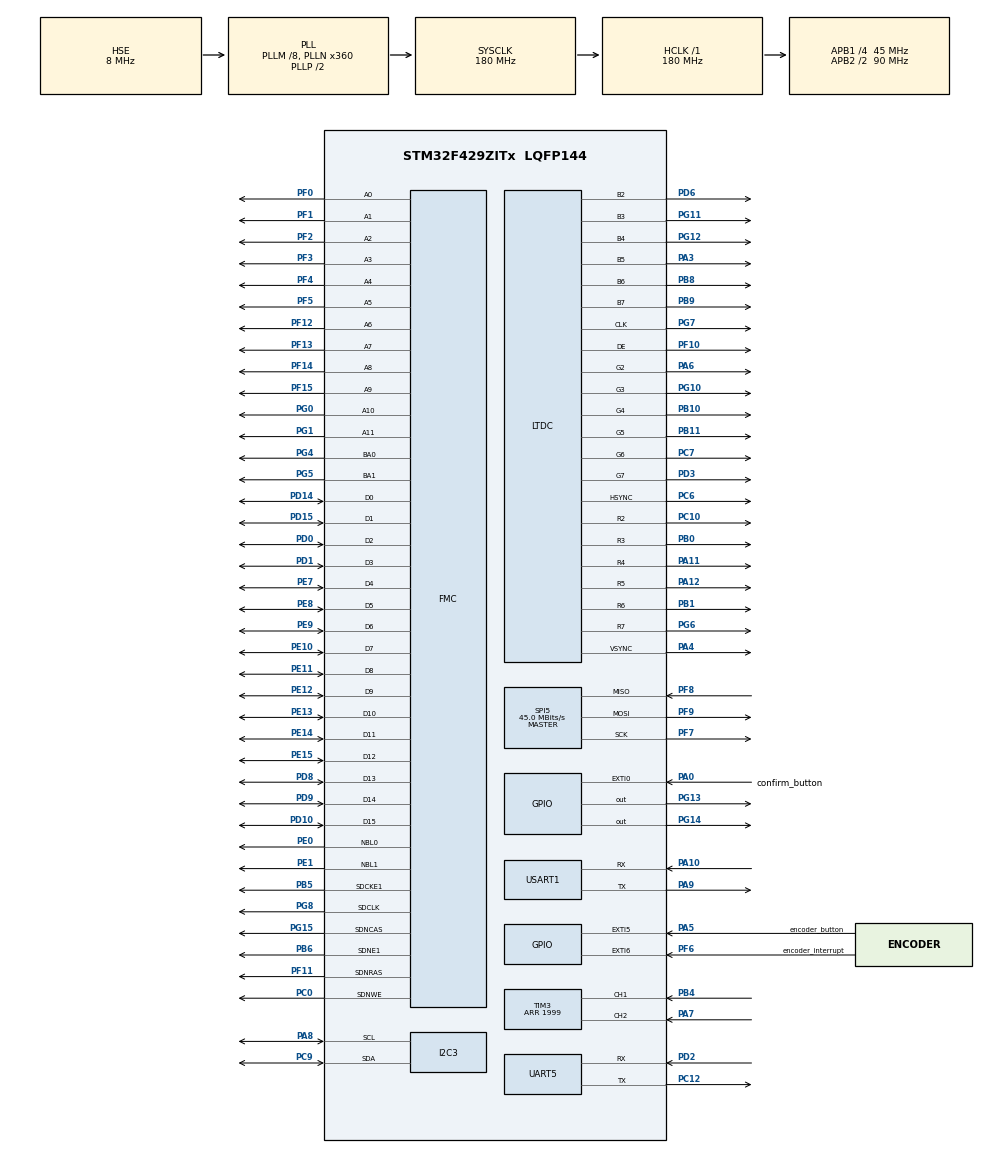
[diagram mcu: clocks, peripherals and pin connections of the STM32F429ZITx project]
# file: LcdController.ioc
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DMA2D.ColorMode=DMA2D_OUTPUT_RGB565
LTDC.ActiveH=320
LTDC.ActiveW=240
Mcu.Family=STM32F4
Mcu.Name=STM32F429ZITx
Mcu.Package=LQFP144
NVIC.EXTI0_IRQn=true\:1\:0\:true\:false\:true\:true\:true\:true
NVIC.EXTI9_5_IRQn=true\:2\:0\:true\:false\:true\:true\:true\:true
NVIC.PriorityGroup=NVIC_PRIORITYGROUP_4
NVIC.UART5_IRQn=true\:0\:0\:true\:false\:true\:true\:true\:true
PA0/WKUP.GPIO_Label=confirm_button
PA0/WKUP.GPIO_ModeDefaultEXTI=GPIO_MODE_IT_RISING
PA0/WKUP.GPIO_PuPd=GPIO_PULLDOWN
PA0/WKUP.Signal=GPXTI0
PA10.Mode=Asynchronous
PA10.Signal=USART1_RX
PA11.Mode=RGB666
PA11.Signal=LTDC_R4
PA12.Mode=RGB666
PA12.Signal=LTDC_R5
PA3.Mode=RGB666
PA3.Signal=LTDC_B5
PA4.Mode=RGB666
PA4.Signal=LTDC_VSYNC
PA5.GPIO_Label=encoder_button
PA5.GPIO_ModeDefaultEXTI=GPIO_MODE_IT_FALLING
PA5.GPIO_PuPd=GPIO_NOPULL
PA5.Signal=GPXTI5
PA6.Mode=RGB666
PA6.Signal=LTDC_G2
PA7.Signal=S_TIM3_CH2
PA8.Mode=I2C
PA8.Signal=I2C3_SCL
PA9.Mode=Asynchronous
PA9.Signal=USART1_TX
PB0.Mode=RGB666
PB0.Signal=LTDC_R3
PB1.Mode=RGB666
PB1.Signal=LTDC_R6
PB10.Mode=RGB666
PB10.Signal=LTDC_G4
PB11.Mode=RGB666
PB11.Signal=LTDC_G5
PB4.Signal=S_TIM3_CH1
PB5.Mode=SdramChipSelect2_1
PB5.Signal=FMC_SDCKE1
PB6.Mode=SdramChipSelect2_1
PB6.Signal=FMC_SDNE1
PB8.Mode=RGB666
PB8.Signal=LTDC_B6
PB9.Mode=RGB666
PB9.Signal=LTDC_B7
PC0.Signal=FMC_SDNWE
PC10.Mode=RGB666
PC10.Signal=LTDC_R2
PC12.Mode=Asynchronous
PC12.Signal=UART5_TX
PC6.Mode=RGB666
PC6.Signal=LTDC_HSYNC
PC7.Mode=RGB666
PC7.Signal=LTDC_G6
PC9.Mode=I2C
PC9.Signal=I2C3_SDA
PD0.Signal=FMC_D2_DA2
PD1.Signal=FMC_D3_DA3
PD10.Signal=FMC_D15_DA15
PD14.Signal=FMC_D0_DA0
PD15.Signal=FMC_D1_DA1
PD2.Mode=Asynchronous
PD2.Signal=UART5_RX
PD3.Mode=RGB666
PD3.Signal=LTDC_G7
PD6.Mode=RGB666
PD6.Signal=LTDC_B2
PD8.Signal=FMC_D13_DA13
PD9.Signal=FMC_D14_DA14
PE0.Signal=FMC_NBL0
PE1.Signal=FMC_NBL1
PE10.Signal=FMC_D7_DA7
PE11.Signal=FMC_D8_DA8
PE12.Signal=FMC_D9_DA9
PE13.Signal=FMC_D10_DA10
PE14.Signal=FMC_D11_DA11
PE15.Signal=FMC_D12_DA12
PE7.Signal=FMC_D4_DA4
PE8.Signal=FMC_D5_DA5
PE9.Signal=FMC_D6_DA6
PF0.Signal=FMC_A0
PF1.Signal=FMC_A1
PF10.Mode=RGB666
PF10.Signal=LTDC_DE
PF11.Signal=FMC_SDNRAS
PF12.Signal=FMC_A6
PF13.Signal=FMC_A7
PF14.Signal=FMC_A8
PF15.Signal=FMC_A9
PF2.Signal=FMC_A2
PF3.Signal=FMC_A3
PF4.Signal=FMC_A4
PF5.Signal=FMC_A5
PF6.GPIO_Label=encoder_interrupt
PF6.GPIO_ModeDefaultEXTI=GPIO_MODE_IT_FALLING
PF6.Signal=GPXTI6
PF7.Mode=Full_Duplex_Master
PF7.Signal=SPI5_SCK
PF8.Mode=Full_Duplex_Master
PF8.Signal=SPI5_MISO
PF9.Mode=Full_Duplex_Master
PF9.Signal=SPI5_MOSI
PG0.Signal=FMC_A10
PG1.Signal=FMC_A11
PG10.Mode=RGB666
PG10.Signal=LTDC_G3
PG11.Mode=RGB666
PG11.Signal=LTDC_B3
PG12.Mode=RGB666
PG12.Signal=LTDC_B4
PG13.Signal=GPIO_Output
PG14.Signal=GPIO_Output
PG15.Signal=FMC_SDNCAS
PG4.Signal=FMC_A14_BA0
PG5.Signal=FMC_A15_BA1
PG6.Mode=RGB666
PG6.Signal=LTDC_R7
PG7.Mode=RGB666
PG7.Signal=LTDC_CLK
PG8.Signal=FMC_SDCLK
PH0/OSC_IN.Mode=HSE-External-Oscillator
PH0/OSC_IN.Signal=RCC_OSC_IN
PH1/OSC_OUT.Mode=HSE-External-Oscillator
PH1/OSC_OUT.Signal=RCC_OSC_OUT
ProjectManager.HeapSize=0x200
ProjectManager.StackSize=0x400
ProjectManager.TargetToolchain=EWARM V8.50
RCC.48MHZClocksFreq_Value=90000000
RCC.AHBFreq_Value=180000000
RCC.APB1CLKDivider=RCC_HCLK_DIV4
RCC.APB1Freq_Value=45000000
RCC.APB1TimFreq_Value=90000000
RCC.APB2CLKDivider=RCC_HCLK_DIV2
RCC.APB2Freq_Value=90000000
RCC.APB2TimFreq_Value=180000000
RCC.CortexFreq_Value=180000000
RCC.HCLKFreq_Value=180000000
RCC.HSE_VALUE=8000000
RCC.HSI_VALUE=16000000
RCC.LSE_VALUE=32768
RCC.PLLM=8
RCC.PLLN=360
RCC.PLLSAIDivR=RCC_PLLSAIDIVR_16
RCC.PLLSAIN=192
RCC.PLLSourceVirtual=RCC_PLLSOURCE_HSE
RCC.SYSCLKFreq_VALUE=180000000
RCC.SYSCLKSource=RCC_SYSCLKSOURCE_PLLCLK
RCC.VCOOutputFreq_Value=360000000
SH.FMC_A0.0=FMC_A0,12b-sda1
SH.FMC_A1.0=FMC_A1,12b-sda1
SH.FMC_A10.0=FMC_A10,12b-sda1
SH.FMC_A11.0=FMC_A11,12b-sda1
SH.FMC_A14_BA0.0=FMC_BA0,FourSdramBanks1
SH.FMC_A15_BA1.0=FMC_BA1,FourSdramBanks1
SH.FMC_A2.0=FMC_A2,12b-sda1
SH.FMC_A3.0=FMC_A3,12b-sda1
SH.FMC_A4.0=FMC_A4,12b-sda1
SH.FMC_A5.0=FMC_A5,12b-sda1
SH.FMC_A6.0=FMC_A6,12b-sda1
SH.FMC_A7.0=FMC_A7,12b-sda1
SH.FMC_A8.0=FMC_A8,12b-sda1
SH.FMC_A9.0=FMC_A9,12b-sda1
SH.FMC_D0_DA0.0=FMC_D0,sd-16b-d1
SH.FMC_D10_DA10.0=FMC_D10,sd-16b-d1
SH.FMC_D11_DA11.0=FMC_D11,sd-16b-d1
SH.FMC_D12_DA12.0=FMC_D12,sd-16b-d1
SH.FMC_D13_DA13.0=FMC_D13,sd-16b-d1
SH.FMC_D14_DA14.0=FMC_D14,sd-16b-d1
SH.FMC_D15_DA15.0=FMC_D15,sd-16b-d1
SH.FMC_D1_DA1.0=FMC_D1,sd-16b-d1
SH.FMC_D2_DA2.0=FMC_D2,sd-16b-d1
SH.FMC_D3_DA3.0=FMC_D3,sd-16b-d1
SH.FMC_D4_DA4.0=FMC_D4,sd-16b-d1
SH.FMC_D5_DA5.0=FMC_D5,sd-16b-d1
SH.FMC_D6_DA6.0=FMC_D6,sd-16b-d1
SH.FMC_D7_DA7.0=FMC_D7,sd-16b-d1
SH.FMC_D8_DA8.0=FMC_D8,sd-16b-d1
SH.FMC_D9_DA9.0=FMC_D9,sd-16b-d1
SH.FMC_NBL0.0=FMC_NBL0,Sd2ByteEnable1
SH.FMC_NBL1.0=FMC_NBL1,Sd2ByteEnable1
SH.FMC_SDCLK.0=FMC_SDCLK,12b-sda1
SH.FMC_SDNCAS.0=FMC_SDNCAS,12b-sda1
SH.FMC_SDNRAS.0=FMC_SDNRAS,12b-sda1
SH.FMC_SDNWE.0=FMC_SDNWE,12b-sda1
SH.S_TIM3_CH1.0=TIM3_CH1,Encoder_Interface
SH.S_TIM3_CH2.0=TIM3_CH2,Encoder_Interface
SPI5.BaudRatePrescaler=SPI_BAUDRATEPRESCALER_2
SPI5.CalculateBaudRate=45.0 MBits/s
SPI5.Direction=SPI_DIRECTION_2LINES
SPI5.Mode=SPI_MODE_MASTER
SPI5.VirtualType=VM_MASTER
TIM3.EncoderMode=TIM_ENCODERMODE_TI1
TIM3.IC1Polarity=TIM_ICPOLARITY_FALLING
TIM3.Period=1999
UART5.VirtualMode=Asynchronous
USART1.VirtualMode=VM_ASYNC
VP_DMA2D_VS_DMA2D.Mode=DMA2D_Activate
board=custom

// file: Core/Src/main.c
/* USER CODE BEGIN Header */
/**
 ******************************************************************************
 * @file           : main.c
 * @brief          : Main program body
 ******************************************************************************
 * @attention
 *
 * Copyright (c) 2024 STMicroelectronics.
 * All rights reserved.
 *
 * This software is licensed under terms that can be found in the LICENSE file
 * in the root directory of this software component.
 * If no LICENSE file comes with this software, it is provided AS-IS.
 *
 ******************************************************************************
 */
/* USER CODE END Header */
#include "main.h"
#include "dma2d.h"
#include "i2c.h"
#include "ltdc.h"
#include "spi.h"
#include "tim.h"
#include "usart.h"
#include "gpio.h"
#include "fmc.h"

/* USER CODE BEGIN Includes */
#include "lcd_menu.h"
#include "communication.h"

#include <stdio.h>
#include <string.h>
#include <stdlib.h>

/* USER CODE END Includes */

/* USER CODE BEGIN PV */
uint16_t encoder_previous_count = 0;

char msg[64];   // debug usart1 message frame
uint16_t count; // encoder counter
uint8_t menu_choice = 0;
enum Main_menu_type actual_menu_type = MAIN;

// parameters
int16_t p = 0;
int16_t v = 0;
int32_t kp = 0;
int16_t kd = 0;
int16_t t = 0;

int16_t angle = 0;
int16_t velocity = 0;

// constants
const float Kp_const = 18.0;
const float Kd_const = 2.0;

// parameters constraints
const int16_t P_MAX = 1250;
const int16_t P_MIN = -1250;

const int16_t angle_MAX = 1000;
const int16_t angle_MIN = -1000;

const uint16_t velocity_MAX = 1500;
const uint16_t velocity_MIN = 0;

const int16_t V_MAX = 4500;
const int16_t V_MIN = -4500;

const int16_t T_MAX = 1800;
const int16_t T_MIN = -1800;

const int32_t KP_MAX = 50000;
const int8_t KP_MIN = 0;

const int16_t KD_MAX = 500;
const int8_t KD_MIN = 0;

// can ID
uint8_t can_id = 0;

const uint8_t CAN_ID_MAX = 12;
const uint8_t CAN_ID_MIN = 0;

// reading motor parameters
volatile uint8_t id_sensor;
volatile float p_sensor;
volatile float v_sensor;
volatile float i_sensor;
volatile uint8_t T_sensor;

/* USER CODE END PV */

void SystemClock_Config(void);

/* USER CODE BEGIN 0 */

// this function is used to refresh p, v, Kp, Kd, t parameters
void refresh_parameters();

/* USER CODE END 0 */

int main(void)
{

  /* MCU Configuration--------------------------------------------------------*/

  /* Reset of all peripherals, Initializes the Flash interface and the Systick. */
  HAL_Init();

  /* Configure the system clock */
  SystemClock_Config();

  /* Initialize all configured peripherals */
  MX_GPIO_Init();
  MX_DMA2D_Init();
  MX_FMC_Init();
  MX_I2C3_Init();
  MX_LTDC_Init();
  MX_SPI5_Init();
  MX_USART1_UART_Init();
  MX_TIM3_Init();
  MX_UART5_Init();

  /* Infinite loop */
  /* USER CODE BEGIN WHILE */
  lcd_initialization();

  HAL_TIM_Encoder_Start(&htim3, TIM_CHANNEL_ALL);
  HAL_Delay(1000);
  // lcd_main_menu(actual_menu_type);

  // activate interrupt for uart receiveing data
  HAL_UART_Receive_IT(&huart5, receiveing_buffer, RECEIVEING_BUFFER_SIZE);

  while (1)
  {
    count = __HAL_TIM_GET_COUNTER(&htim3);
    count /= 2;

    refresh_parameters();

    // sprintf((char *)msg, "Encoder: %d, P: %d, V: %d\n\r", count, p, v);
    // HAL_UART_Transmit(&huart1, (uint8_t *)msg, strlen(msg), 1000);
    /* USER CODE END WHILE */

    /* USER CODE BEGIN 3 */
    HAL_GPIO_TogglePin(GPIOG, GPIO_PIN_14);
  }
  /* USER CODE END 3 */
}

void SystemClock_Config(void)
{
  RCC_OscInitTypeDef RCC_OscInitStruct = {0};
  RCC_ClkInitTypeDef RCC_ClkInitStruct = {0};

  /** Configure the main internal regulator output voltage
  */
  __HAL_RCC_PWR_CLK_ENABLE();
  __HAL_PWR_VOLTAGESCALING_CONFIG(PWR_REGULATOR_VOLTAGE_SCALE1);

  /** Initializes the RCC Oscillators according to the specified parameters
  * in the RCC_OscInitTypeDef structure.
  */
  RCC_OscInitStruct.OscillatorType = RCC_OSCILLATORTYPE_HSE;
  RCC_OscInitStruct.HSEState = RCC_HSE_ON;
  RCC_OscInitStruct.PLL.PLLState = RCC_PLL_ON;
  RCC_OscInitStruct.PLL.PLLSource = RCC_PLLSOURCE_HSE;
  RCC_OscInitStruct.PLL.PLLM = 8;
  RCC_OscInitStruct.PLL.PLLN = 360;
  RCC_OscInitStruct.PLL.PLLP = RCC_PLLP_DIV2;
  RCC_OscInitStruct.PLL.PLLQ = 4;
  if (HAL_RCC_OscConfig(&RCC_OscInitStruct) != HAL_OK)
  {
    Error_Handler();
  }

  /** Activate the Over-Drive mode
  */
  if (HAL_PWREx_EnableOverDrive() != HAL_OK)
  {
    Error_Handler();
  }

  /** Initializes the CPU, AHB and APB buses clocks
  */
  RCC_ClkInitStruct.ClockType = RCC_CLOCKTYPE_HCLK|RCC_CLOCKTYPE_SYSCLK
                              |RCC_CLOCKTYPE_PCLK1|RCC_CLOCKTYPE_PCLK2;
  RCC_ClkInitStruct.SYSCLKSource = RCC_SYSCLKSOURCE_PLLCLK;
  RCC_ClkInitStruct.AHBCLKDivider = RCC_SYSCLK_DIV1;
  RCC_ClkInitStruct.APB1CLKDivider = RCC_HCLK_DIV4;
  RCC_ClkInitStruct.APB2CLKDivider = RCC_HCLK_DIV2;

  if (HAL_RCC_ClockConfig(&RCC_ClkInitStruct, FLASH_LATENCY_5) != HAL_OK)
  {
    Error_Handler();
  }
}

/* USER CODE BEGIN 4 */
uint32_t previousTime = 0;
uint32_t currentTime = 0;

void HAL_GPIO_EXTI_Callback(uint16_t GPIO_Pin)
{
  currentTime = HAL_GetTick();

  if (GPIO_Pin == encoder_button_Pin && (currentTime - previousTime > 100))
  {
    previousTime = currentTime;

    HAL_GPIO_TogglePin(GPIOG, GPIO_PIN_13);

    if (actual_menu_type == MAIN)
    {
      if (menu_choice > 2)
        menu_choice = 0;
      else
        menu_choice++;
    }

    if (actual_menu_type == PARAMETERS)
    {
      if (menu_choice > 8)
        menu_choice = 0;
      else
        menu_choice++;
    }

    if (actual_menu_type == MOVEMENT)
    {
      if (menu_choice > 2)
        menu_choice = 0;
      else
        menu_choice++;
    }

    if (actual_menu_type == SENSORS)
    {
      if (menu_choice > 1)
        menu_choice = 0;
      else
        menu_choice++;
    }
  }

  if (GPIO_Pin == confirm_button_Pin && (currentTime - previousTime > 100))
  {
    previousTime = currentTime;

    if (actual_menu_type == MAIN)
    {
      actual_menu_type = menu_choice + 1;
      menu_choice = 0;
    }

    // for back button (returning to MIAN menu)
    if (actual_menu_type == PARAMETERS && menu_choice == 8)
    {
      actual_menu_type = MAIN;
      menu_choice = 0;
    }

    if (actual_menu_type == MOVEMENT && menu_choice == 2)
    {
      actual_menu_type = MAIN;
      menu_choice = 0;
    }

    if (actual_menu_type == SENSORS && menu_choice == 1)
    {
      actual_menu_type = MAIN;
      menu_choice = 0;
    }

    // start motor
    if (actual_menu_type == PARAMETERS && menu_choice == 5)
    {
      set_can_ID(can_id);
      start_engin();
      send_buffer(&huart5);
    }

    // stop motor
    if (actual_menu_type == PARAMETERS && menu_choice == 6)
    {
      set_can_ID(can_id);
      stop_engin();
      send_buffer(&huart5);
    }

    // send data
    if (actual_menu_type == PARAMETERS && menu_choice == 7)
    {
      load_data(p / 100., v / 100., kp / 100., kd / 100., t / 100.);
      send_buffer(&huart5);
    }

    HAL_GPIO_TogglePin(GPIOG, GPIO_PIN_13);
  }

  if (GPIO_Pin == encoder_interrupt_Pin)
  {
    // Angle controle mode
    if (actual_menu_type == MOVEMENT && menu_choice == 0)
    {
      load_data(angle / 100., 0.0, Kp_const, Kd_const, 0.0);
      send_buffer(&huart5);
    }

    // Velocity controle mode
    if (actual_menu_type == MOVEMENT && menu_choice == 1)
    {
      load_data(0., velocity / 100., 0., 4.7, 0.);
      send_buffer(&huart5);
    }

    // useful to debug
    // sprintf((char *)msg, "Encoder: %d, Different: %d, P: %d, V: %d, flag: %d\n\r", count, counter_different, p, v, addition_flag);
    // HAL_UART_Transmit(&huart1, (uint8_t *)msg, strlen(msg), 1000);
  }

  lcd_refresh_UJ(actual_menu_type, menu_choice);
}

void refresh_parameters()
{
  set_can_ID(can_id);

  int16_t counter_different = count - encoder_previous_count;

  // when occures overload of encoder rotation counter
  if (abs(counter_different) > 1900)
    counter_different = 1;

  // int8_t addition_flag = 1;
  // if (counter_different < 0)
  // {
  //   addition_flag = -1;
  //   counter_different *= -1;
  // }

  // angle
  if (actual_menu_type == MOVEMENT && menu_choice == 0)
  {
    // angle += (10 * counter_different * addition_flag);
    angle += (10 * counter_different);

    if (angle > angle_MAX)
      angle = 1000;

    if (angle < angle_MIN)
      angle = -1000;
  }

  // velocity
  if (actual_menu_type == MOVEMENT && menu_choice == 1)
  {
    velocity += (10 * counter_different);

    if (velocity > velocity_MAX)
      velocity = velocity_MAX;

    if (velocity < velocity_MIN)
      velocity = velocity_MIN;
  }

  // for P value
  if (actual_menu_type == PARAMETERS && menu_choice == 0)
  {
    // p += (10 * counter_different * addition_flag);
    p += (10 * counter_different);

    if (p > P_MAX)
      p = P_MAX;

    if (p < P_MIN)
      p = P_MIN;
  }

  // for V value
  if (actual_menu_type == PARAMETERS && menu_choice == 1)
  {
    // v += (10 * counter_different * addition_flag);
    v += (10 * counter_different);

    if (v > V_MAX)
      v = V_MAX;

    if (v < V_MIN)
      v = V_MIN;
  }

  // for Kp value
  if (actual_menu_type == PARAMETERS && menu_choice == 2)
  {
    // kp += (10 * counter_different * addition_flag);
    kp += (10 * counter_different);

    if (kp > KP_MAX)
      kp = KP_MAX;

    if (kp < KP_MIN)
      kp = KP_MIN;
  }

  // for KD value
  if (actual_menu_type == PARAMETERS && menu_choice == 3)
  {
    // kd += (10 * counter_different * addition_flag);
    kd += (10 * counter_different);

    if (kd > KD_MAX)
      kd = KD_MAX;

    if (kd < KD_MIN)
      kd = KD_MIN;
  }

  // for t value
  if (actual_menu_type == PARAMETERS && menu_choice == 4)
  {
    // t += (10 * counter_different * addition_flag);
    t += (10 * counter_different);

    if (t > T_MAX)
      t = T_MAX;

    if (t < T_MIN)
      t = T_MIN;
  }

  // for increasing or decreasing can id
  if (actual_menu_type == MAIN && menu_choice == 3)
  {
    // can_id += counter_different * addition_flag;
    can_id += counter_different;

    if (can_id > CAN_ID_MAX)
      can_id = CAN_ID_MAX;
  }

  if (counter_different != 0)
    lcd_refresh_UJ(actual_menu_type, menu_choice);

  encoder_previous_count = count;
}

void HAL_UART_RxCpltCallback(UART_HandleTypeDef *huart)
{
  if (huart->Instance == UART5)
  {
    parse_uart_buffer(receiveing_buffer, &id_sensor, &p_sensor, &v_sensor, &i_sensor, &T_sensor);

    HAL_UART_Receive_IT(&huart5, receiveing_buffer, RECEIVEING_BUFFER_SIZE);
  }
}

/* USER CODE END 4 */

void Error_Handler(void)
{
  __disable_irq();
  while (1)
  {
  }
}
